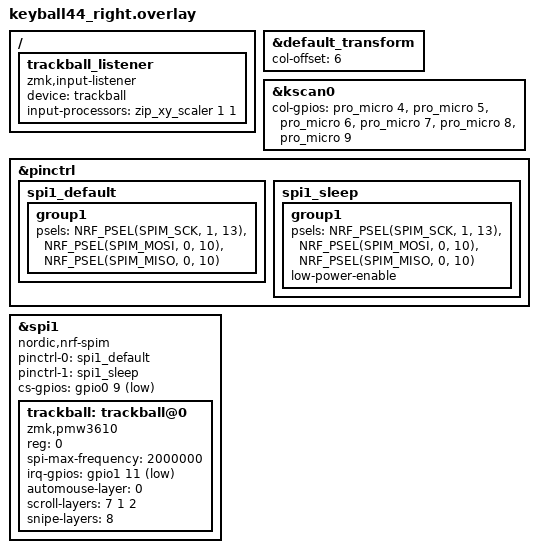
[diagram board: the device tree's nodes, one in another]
/*
 * Copyright (c) 2020 ZMK Contributors
 *
 * SPDX-License-Identifier: MIT
 */
 
#include "keyball44.dtsi"
#include <input/processors.dtsi>

&default_transform {
    col-offset = <6>;
};

&kscan0 {
	col-gpios
		= <&pro_micro 4 GPIO_ACTIVE_HIGH>
		, <&pro_micro 5 GPIO_ACTIVE_HIGH>
		, <&pro_micro 6 GPIO_ACTIVE_HIGH>
		, <&pro_micro 7 GPIO_ACTIVE_HIGH>
		, <&pro_micro 8 GPIO_ACTIVE_HIGH>
        , <&pro_micro 9 GPIO_ACTIVE_HIGH>
		;
};

&pinctrl {
    spi1_default: spi1_default {
        group1 {
            psels = <NRF_PSEL(SPIM_SCK, 1, 13)>,
                <NRF_PSEL(SPIM_MOSI, 0, 10)>,
                <NRF_PSEL(SPIM_MISO, 0, 10)>;
        };
    };

    spi1_sleep: spi1_sleep {
        group1 {
            psels = <NRF_PSEL(SPIM_SCK, 1, 13)>,
                <NRF_PSEL(SPIM_MOSI, 0, 10)>,
                <NRF_PSEL(SPIM_MISO, 0, 10)>;
            low-power-enable;
        };
    };
};

&spi1 {
    status = "okay";
    compatible = "nordic,nrf-spim";
    pinctrl-0 = <&spi1_default>;
    pinctrl-1 = <&spi1_sleep>;
    pinctrl-names = "default", "sleep";
    cs-gpios = <&gpio0 9 GPIO_ACTIVE_LOW>;

    trackball: trackball@0 {
        status = "okay";
        compatible = "zmk,pmw3610";
        reg = <0>;
        spi-max-frequency = <2000000>;
        irq-gpios = <&gpio1 11 (GPIO_ACTIVE_LOW | GPIO_PULL_UP)>;
	/* Layer indices must match config/keyball44.keymap:
	   6=MOUSE, 7=SCROLL, 1=NAV, 2=SELECT, 8=SNIPE.
	   NAV/SELECT in scroll-layers = ball scrolls while the mod key is held. */
	/* 0 disables the auto-mouse layer outright (the driver guards the whole
	   mechanism with #if AUTOMOUSE_LAYER > 0). Clicks are on dedicated keys
	   now, so nothing needs the ball to flip a layer — and this removes stray
	   clicks from brushing the ball while typing. Layer 6 still exists in the
	   keymap because SCROLL and SNIPE are indexed off it. */
	automouse-layer = <0>;
	scroll-layers = <7 1 2>;
	snipe-layers = <8>;
    };
};

/ {
  trackball_listener {
    compatible = "zmk,input-listener";
    device = <&trackball>;

    /* Left at 1/1 deliberately. Any ratio below 1 quantises slow movement: the
       sensor emits roughly one count per report when moving slowly, and a
       fractional ratio makes some of those reports emit zero pixels, so small
       movements arrive in steps while fast ones stay smooth. Set speed with
       CONFIG_PMW3610_CPI instead and leave this alone. If a speed between two
       200-CPI steps is genuinely needed, 7/8 is the gentlest ratio worth using;
       anything nearer 1/2 is visibly jolty. Only REL_X/REL_Y are matched, so
       scroll is unaffected either way. */
    input-processors = <&zip_xy_scaler 1 1>;
  };
};
